# STM32WL5X_CM4 register map
File version: 2.2
CPU: CM4 r0p1, little endian, MPU, no FPU, 4 interrupt priority bits
Registers are 32-bit, read-write, reset 0x0 unless marked. A register's access mark holds for its fields unless they carry their own. Offsets are from the block's base; [hi:lo] are bit positions; 'fields as' and 'values as' point back to an identical list.

## CRC — Cyclic redundancy check calculation unit
Base 0x40023000
0x00 DR reset 0xFFFFFFFF — Data register
  [31:0] DR — Data register bits
0x00 DR8 8-bit reset 0xFF (alternate view of DR) — Data register - byte sized
  [7:0] DR8 — Data register bits
0x00 DR16 16-bit reset 0xFFFF (alternate view of DR) — Data register - half-word sized
  [15:0] DR16 — Data register bits
0x04 IDR — Independent data register
  [31:0] IDR — General-purpose 32-bit data register bits
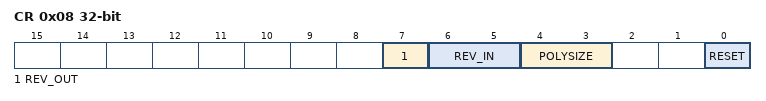
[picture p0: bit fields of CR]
0x08 CR — Control register
  [7] REV_OUT — Reverse output data
    0=Normal (Bit order not affected); 1=Reversed (Bit reversed output)
  [6:5] REV_IN — Reverse input data
    0=Normal (Bit order not affected); 1=Byte (Bit reversal done by byte); 2=HalfWord (Bit reversal done by half-word); 3=Word (Bit reversal done by word)
  [4:3] POLYSIZE — Polynomial size
    0=32-bit polynomial; 1=16-bit polynomial; 2=8-bit polynomial; 3=7-bit polynomial
  [0] RESET — RESET bit
    on write: 1=Resets the CRC calculation unit and sets the data register to 0xFFFF FFFF
0x10 INIT reset 0xFFFFFFFF — Initial CRC value
  [31:0] INIT — Programmable initial CRC value
0x14 POL reset 0x4C11DB7 — polynomial
  [31:0] POL — Programmable polynomial

## DBGMCU — Microcontroller Debug Unit
Base 0xE0042000
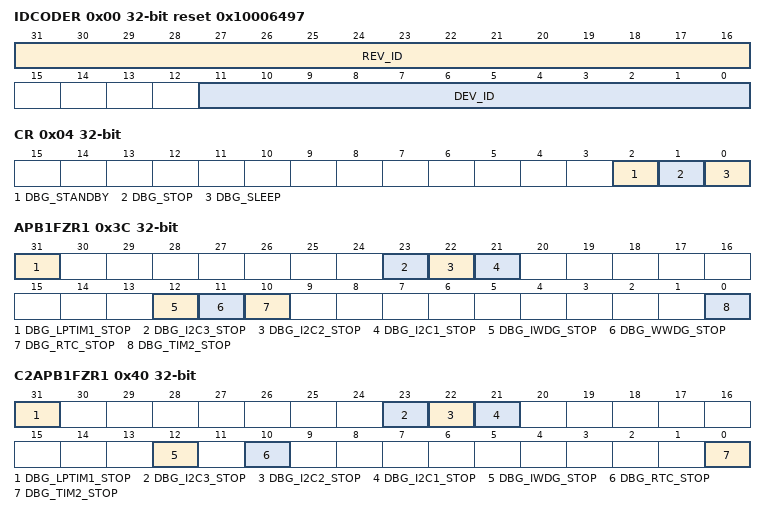
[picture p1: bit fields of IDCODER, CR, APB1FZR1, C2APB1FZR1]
0x00 IDCODER ro reset 0x10006497 — DBGMCU Identity Code Register
  [31:16] REV_ID — Revision
  [11:0] DEV_ID — Device ID
0x04 CR — DBGMCU Configuration Register
  [2] DBG_STANDBY — Allow debug in STANDBY mode
    0=Disabled (Debug Standby Mode Disabled); 1=Enabled (Debug Standby Mode Enabled)
  [1] DBG_STOP — Allow debug in STOP mode
    0=Disabled (Debug Stop Mode Disabled); 1=Enabled (Debug Stop Mode Enabled)
  [0] DBG_SLEEP — Allow debug in SLEEP mode
    0=Disabled (Debug Sleep Mode Disabled); 1=Enabled (Debug Sleep Mode Enabled)
0x3C APB1FZR1 — DBGMCU CPU1 APB1 Peripheral Freeze Register 1
  [31] DBG_LPTIM1_STOP — LPTIM1 stop in CPU1 debug
    0=Continue (LPTIMx counter clock is fed even if the core is halted); 1=Stop (LPTIMx counter clock is stopped when the core is halted)
  [23] DBG_I2C3_STOP — I2C3 SMBUS timeout stop in CPU1 debug
    0=NormalMode (Same behavior as in normal mode); 1=SMBusTimeoutFrozen (I2Cx SMBUS timeout is frozen)
  [22] DBG_I2C2_STOP — I2C2 SMBUS timeout stop in CPU1 debug
    values as DBG_I2C3_STOP
  [21] DBG_I2C1_STOP — I2C1 SMBUS timeout stop in CPU1 debug
    values as DBG_I2C3_STOP
  [12] DBG_IWDG_STOP — IWDG stop in CPU1 debug
    0=Continue (The independent watchdog counter clock continues even if the core is halted); 1=Stop (The independent watchdog counter clock is stopped when the core is halted)
  [11] DBG_WWDG_STOP — WWDG stop in CPU1 debug
    0=Continue (The window watchdog counter clock continues even if the core is halted); 1=Stop (The window watchdog counter clock is stopped when the core is halted)
  [10] DBG_RTC_STOP — RTC stop in CPU1 debug
    0=Continue (The clock of the RTC counter is fed even if the core is halted); 1=Stop (The clock of the RTC counter is stopped when the core is halted)
  [0] DBG_TIM2_STOP — TIM2 stop in CPU1 debug
    0=Continue (The counter clock of TIMx is fed even if the core is halted); 1=Stop (The counter clock of TIMx is stopped when the core is halted)
0x40 C2APB1FZR1 — DBGMCU CPU2 APB1 Peripheral Freeze Register 1 [dual core device
  [31] DBG_LPTIM1_STOP, [23] DBG_I2C3_STOP, [22] DBG_I2C2_STOP, [21] DBG_I2C1_STOP, [12] DBG_IWDG_STOP, [10] DBG_RTC_STOP, [0] DBG_TIM2_STOP
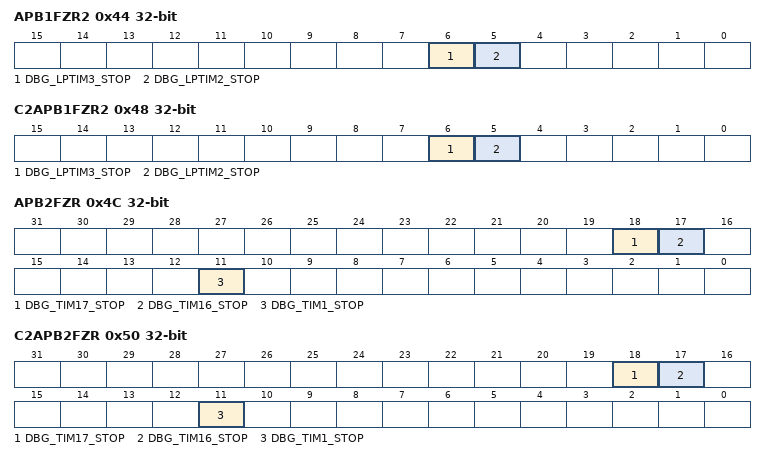
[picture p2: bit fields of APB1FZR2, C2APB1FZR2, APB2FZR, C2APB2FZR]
0x44 APB1FZR2 — DBGMCU CPU1 APB1 Peripheral Freeze Register 2
  [6] DBG_LPTIM3_STOP
    values as APB1FZR1.DBG_LPTIM1_STOP
  [5] DBG_LPTIM2_STOP
    values as APB1FZR1.DBG_LPTIM1_STOP
0x48 C2APB1FZR2 — DBGMCU CPU2 APB1 Peripheral Freeze Register 2 [dual core device
  [6] DBG_LPTIM3_STOP, [5] DBG_LPTIM2_STOP
0x4C APB2FZR — DBGMCU CPU1 APB2 Peripheral Freeze Register
  [all] fields
    values as APB1FZR1.DBG_TIM2_STOP
  [18] DBG_TIM17_STOP
  [17] DBG_TIM16_STOP
  [11] DBG_TIM1_STOP
0x50 C2APB2FZR — DBGMCU CPU2 APB2 Peripheral Freeze Register [dual core device
  [18] DBG_TIM17_STOP, [17] DBG_TIM16_STOP, [11] DBG_TIM1_STOP
